# ot_i3c_wrap: IP-XACT component
VLNV tenstorrent.com:ocah:ot_i3c_wrap:1.0

## Address spaces and blocks
ot_i3c_wrap_mmap.ot_i3c_wrap: base 'h0, range 'h6000, width 32

## Registers
Registers are 32-bit, read-write, reset 0x0 unless marked. A register's access mark holds for its fields unless they carry their own. Offsets are from the block's base; lines under a group give offsets from that group; [hi:lo] are bit positions; {n}, {i} and the like mark numbered series; 'fields as' and 'values as' point back to an identical list; <NAME> marks a mode.

## ot_i3c_wrap_mmap.ot_i3c_wrap — Wrapper address map instantiating the per-controller OpenTitan I3C register blocks.
Base 0x00000000
{0x0+0x1000*i} i3c_csr[{i}] (i=0..5) group — I3C Controller/Target
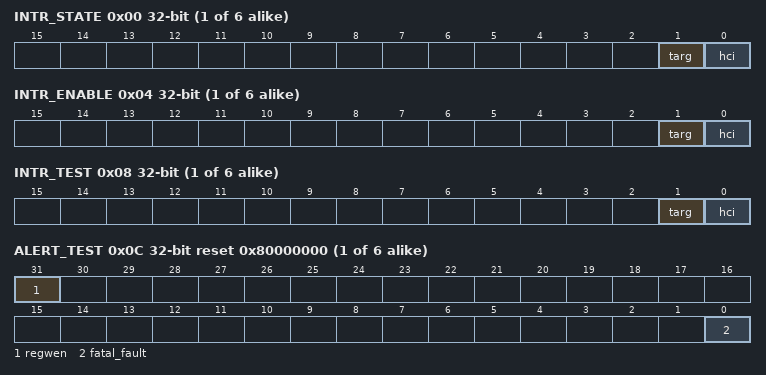
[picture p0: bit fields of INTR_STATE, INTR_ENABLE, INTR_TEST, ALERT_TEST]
  0x00 INTR_STATE ro
    [1] targ — Target interrupt.
    [0] hci — HCI interrupt.
  0x04 INTR_ENABLE
    [1] targ — Enable interrupt when !!INTR_STATE.targ is set.
    [0] hci — Enable interrupt when !!INTR_STATE.hci is set.
  0x08 INTR_TEST wo
    [1] targ — Write 1 to force !!INTR_STATE.targ to 1.
    [0] hci — Write 1 to force !!INTR_STATE.hci to 1.
  0x0C ALERT_TEST access per field reset 0x80000000
    [31] regwen rw write-0-clears — Write 0 to disable alert testing until the next reset.
    [0] fatal_fault wo — Write 1 to trigger one alert event of this kind.
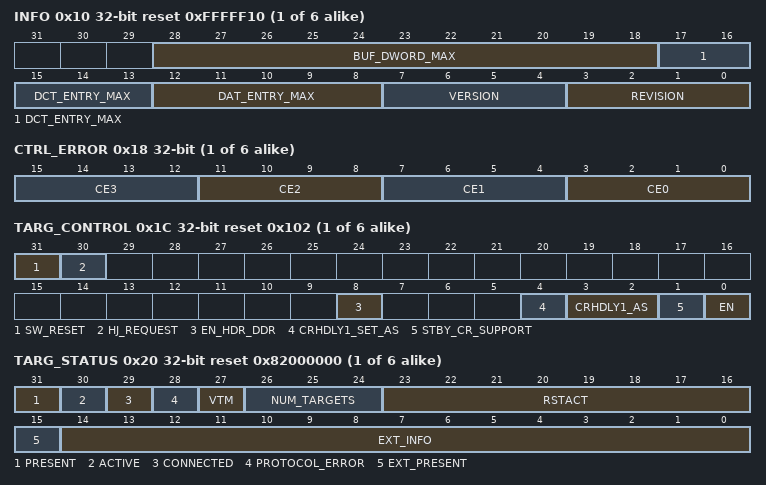
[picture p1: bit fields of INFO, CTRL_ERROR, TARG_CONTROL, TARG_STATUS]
  0x10 INFO ro reset 0xFFFFF10
    [28:18] BUF_DWORD_MAX — Index of the final DWORD of the shared Message Buffer. i.e. one less than its size in DWORDs.
    [17:13] DCT_ENTRY_MAX — Index of the final entry of the HCI Device Characteristics Table. i.e. one less than the number of entries.
    [12:8] DAT_ENTRY_MAX — Index of the final entry of the HCI Device Address Table. i.e. one less than the number of entries.
    [7:4] VERSION — Version number of the IP block.
    [3:0] REVISION — Revision number of the IP block.
  0x14 CTRL_STATUS ro reset 0x80000000
    [31] PRESENT — Indicates the presence of Controller functionality.
  0x18 CTRL_ERROR
    [4n+3:4n] CE{n} write-1-clears (n=0..3) — Count of type {n} Controller Errors.
  0x1C TARG_CONTROL access per field reset 0x102
    [31] SW_RESET wo — Software reset of Target logic. Writing '1' to this field will reset all of the Target-side logic and registers. When the Standby Controller is enabled, this will also reset the registers of the Standby Controller, disabling it. To reset only the Standby Controller whilst it is enabled, software should use the `SOFT_RST` field of the HCI-specified `RESET_CONTROL` register instead, to avoid impacting other Virtual Targets.
    [30] HJ_REQUEST rw — Issue Hot-Join request. This applies to all Virtual Targets since they share a single physical Target. Software shall set this to '1' to issue the request, and the hardware will clear it when the request has been sent and acknowledged.
    [8] EN_HDR_DDR rw — Declare support for HDR-DDR mode in the GETCAPS response of the Target. HDR-DDR mode should normally be enabled, and the ability for software to deactivate HDR-DDR mode is included only as a contingency. This configuration bit shall be modified only before the Target is enabled. For the Controller, the issuing of HDR-DDR communications may be avoided in software by the construction of appropriate Command Descriptors.
    [4] CRHDLY1_SET_AS rw — Set Bus Activity State. This information is returned in response to the CRHDLY form of the GETMXDS CCC.
    [3:2] CRHDLY1_AS rw — Controller Handoff Activity State. This information is returned in response to the CRHDLY form of the GETMXDS CCC.
    [1] STBY_CR_SUPPORT rw — Standby Controller role supported. When set the Controller shall have the option of performing Controller Role Handoff and switching into Standby Controller mode. If this field is clear the Controller will refuse to hand off the bus when requested and will instead remain the Active Controller, thus freeing up the first Virtual Target to operate independently as a dedicated Target device. This version of the IP block does not support Controller Role Handoff.
    [0] EN rw — Target enable. Enable the Target-side logic as a separate I3C device, instead of supporting Standby Controller mode. In this configuration the Controller-side logic must remain the Active Controller and cannot perform Controller Role Handoff.
  0x20 TARG_STATUS access per field reset 0x82000000
    [31] PRESENT ro — Indicates the presence of Target functionality.
    [30] ACTIVE ro — Indicates whether the Target logic is presently active, as opposed to under reset.
    [29] CONNECTED ro — Indicates whether the Target logic is connected to the bus and monitoring traffic.
    [28] PROTOCOL_ERROR ro — Protocol error detected since the last GETSTATUS CCC to read this indicator.
    [27] VTM ro — Vendor Test Mode active, in response to ENTTM.
    [26:24] NUM_TARGETS ro — The number of Targets in this implementation.
    [23:16] RSTACT ro — Configured Target Reset action.
    [15] EXT_PRESENT ro — Indicates whether one or more additional protocols is implemented in the Target hardware. Some protocols require a sufficiently fast response that software involvement is not possible. These may be implemented as an extension within the Target core.
    [14:0] EXT_INFO rw — Extension-specific information.
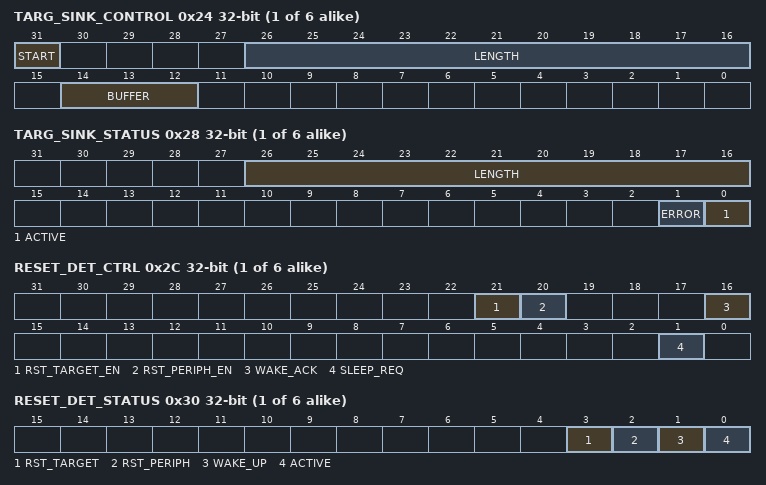
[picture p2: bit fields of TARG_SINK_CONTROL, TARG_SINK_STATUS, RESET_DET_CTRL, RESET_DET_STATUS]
  0x24 TARG_SINK_CONTROL access per field
    [31] START wo — Initiate removal of DWORDs from a transmission buffer. The 'data sink' logic is a mechanism for recovering from aborting or failed transmissions without impacting subsequent, already-queued transfers. Software shall write '1' to this field to start the 'data sink' logic. The ACTIVE field in the corresponding `TARG_SINK_STATUS` register shows whether the logic is still active.
    [26:16] LENGTH rw — Specifies the number of DWORDs to be removed, minus 1. This field instructs the 'data sink' logic to remove a specified number of DWORDs of data from the specified source. Software shall program 'n-1' into this field to remove 'n' DWORDs.
    [14:12] BUFFER rw — Specifies the transmission buffer from which DWORDs are to be removed. 0 - IBI Data buffer. 1 - Virtual Target 0 Tx buffer 2 - Virtual Target 1 Tx buffer...
  0x28 TARG_SINK_STATUS ro
    [26:16] LENGTH — Reports the numbers of DWORDs still to be removed when `ERROR` is asserted. In the event of an error, this value may be used to ascertain how much of the operation was performed. When this field reports 'm', there are still 'm+1' DWORDs to be removed. In the event of successful completion ('ACTIVE' and 'ERROR' both reset) this field is not meaningful and the DWORDs were removed as expected.
    [1] ERROR — Indicates whether the data sink mechanism stopped prematurely. If the specified buffer did not contain sufficient data for the logic to remove the specified number of DWORDs it will set this bit when becoming inactive.
    [0] ACTIVE — Indicates whether the data sink logic is active. This bit becomes set when the operation is started and will be cleared at most a few tens of microseconds later when the operation is complete.
  0x2C RESET_DET_CTRL wo
    [21] RST_TARGET_EN — Enable response to a Whole Target reset request.
    [20] RST_PERIPH_EN — Enable response to a Peripheral reset request.
    [16] WAKE_ACK — Wake acknowledgement.
    [1] SLEEP_REQ — Activate the reset detector prior to entry into 'Deepest Sleep' state.
  0x30 RESET_DET_STATUS ro
    [3] RST_TARGET — Indicates that a Whole Target reset request was received.
    [2] RST_PERIPH — Indicates that a Peripheral reset request was received.
    [1] WAKE_UP — Indicates that a Wake Up request was received.
    [0] ACTIVE — Indicates whether the reset detector is active.
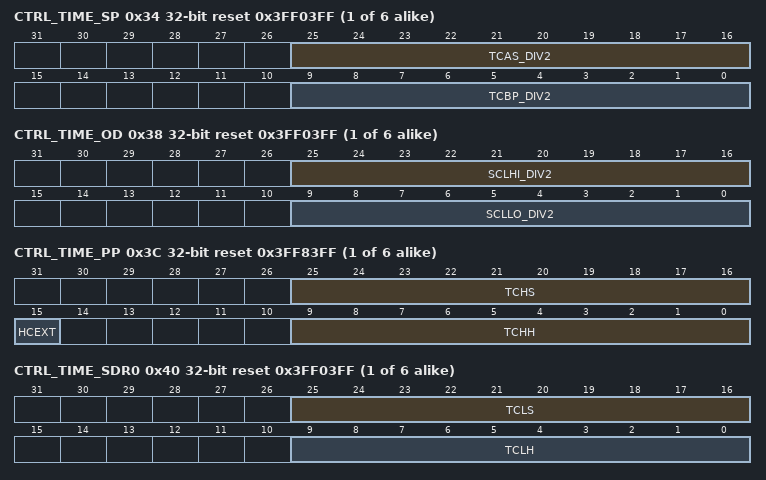
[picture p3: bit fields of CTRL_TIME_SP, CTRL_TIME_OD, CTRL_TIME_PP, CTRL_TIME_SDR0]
  0x34 CTRL_TIME_SP reset 0x3FF03FF
    [25:16] TCAS_DIV2 — Half of the delay between SDA falling and SCL falling in START timing, minus 1. This interval is in terms of the IP clock period. If this field has all bits set then the hardware will calculate a suitable value.
    [9:0] TCBP_DIV2 — Half of the delay between SCL rising and SDA rising in STOP timing, minus 1. This interval is in terms of the IP clock period. If this field has all bits set then the hardware will calculate a suitable value.
  0x38 CTRL_TIME_OD reset 0x3FF03FF
    [25:16] SCLHI_DIV2 — Half of the SCL high interval during Open Drain signaling, minus 1. This interval is in terms of the IP clock period. If this field has all bits set then the hardware will calculate a suitable value.
    [9:0] SCLLO_DIV2 — Half of the SCL low interval during Open Drain signaling, minus 1. This interval is in terms of the IP clock period. If this field has all bits set then the hardware will calculate a suitable value.
  0x3C CTRL_TIME_PP reset 0x3FF83FF
    [25:16] TCHS — Duration of setup phase before falling SCL during Push-Pull signaling, minus 1. This interval is in terms of the IP clock period. If this field has all bits set then the hardware will calculate a suitable value.
    [15] HCEXT — Enable half-cycle SCL extension. If the field `TCHS` has been set to something other than 0x3ff, this bit controls whether the half-cycle SCL extension is enabled. If `TCHS` has all bits set then the hardware will determine this setting automatically. Extending SCL high by half a cycle of the IP clock enables support for other clock frequencies such as 96 MHz.
    [9:0] TCHH — Duration of hold phase after rising SCL during Push-Pull signaling, minus 1. This interval is in terms of the IP clock period. If this field has all bits set then the hardware will calculate a suitable value.
  0x40 CTRL_TIME_SDR0 reset 0x3FF03FF
    [25:16] TCLS — Duration of setup phase before rising SCL when using Push-Pull signaling at SDR0 rate/HDR-DDR, minus 1. This interval is in terms of the IP clock period. If this field has all bits set then the hardware will calculate a suitable value.
    [9:0] TCLH — Duration of hold phase after falling SCL when using Push-Pull signaling at SDR0 rate/HDR-DDR, minus 1. This interval is in terms of the IP clock period. If this field has all bits set then the hardware will calculate a suitable value.
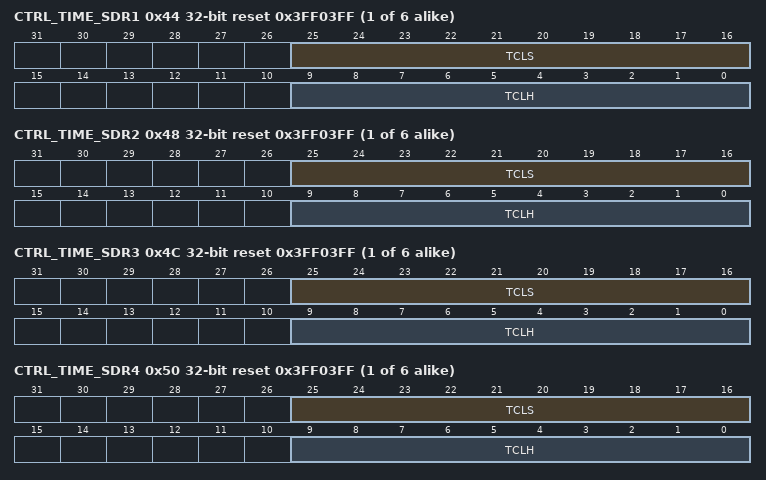
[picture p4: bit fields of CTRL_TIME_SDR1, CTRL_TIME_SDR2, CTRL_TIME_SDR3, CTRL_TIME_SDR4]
  0x44 CTRL_TIME_SDR1 reset 0x3FF03FF
    [25:16] TCLS — Duration of setup phase before rising SCL when using Push-Pull signaling at SDR1 rate, minus 1. This interval is in terms of the IP clock period. If this field has all bits set then the hardware will calculate a suitable value.
    [9:0] TCLH — Duration of hold phase after falling SCL when using Push-Pull signaling at SDR1 rate, minus 1. This interval is in terms of the IP clock period. If this field has all bits set then the hardware will calculate a suitable value.
  0x48 CTRL_TIME_SDR2 reset 0x3FF03FF
    [25:16] TCLS — Duration of setup phase before rising SCL when using Push-Pull signaling at SDR2, minus 1. This interval is in terms of the IP clock period. If this field has all bits set then the hardware will calculate a suitable value.
    [9:0] TCLH — Duration of hold phase after falling SCL when using Push-Pull signaling at SDR2 rate, minus 1. This interval is in terms of the IP clock period. If this field has all bits set then the hardware will calculate a suitable value.
  0x4C CTRL_TIME_SDR3 reset 0x3FF03FF
    [25:16] TCLS — Duration of setup phase before rising SCL when using Push-Pull signaling at SDR3 rate, minus 1. This interval is in terms of the IP clock period. If this field has all bits set then the hardware will calculate a suitable value.
    [9:0] TCLH — Duration of hold phase after falling SCL when using Push-Pull signaling at SDR3 rate, minus 1. This interval is in terms of the IP clock period. If this field has all bits set then the hardware will calculate a suitable value.
  0x50 CTRL_TIME_SDR4 reset 0x3FF03FF
    [25:16] TCLS — Duration of setup phase before rising SCL when using Push-Pull signaling at SDR4 rate, minus 1. This interval is in terms of the IP clock period. If this field has all bits set then the hardware will calculate a suitable value.
    [9:0] TCLH — Duration of hold phase after falling SCL when using Push-Pull signaling at SDR4 rate, minus 1. This interval is in terms of the IP clock period. If this field has all bits set then the hardware will calculate a suitable value.
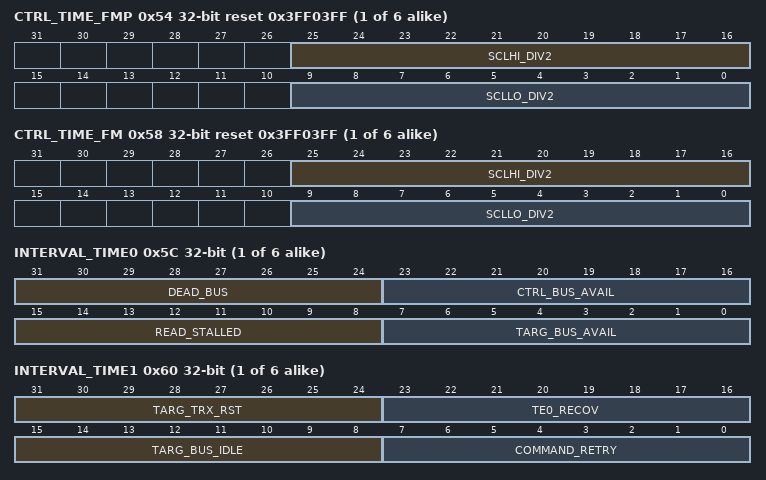
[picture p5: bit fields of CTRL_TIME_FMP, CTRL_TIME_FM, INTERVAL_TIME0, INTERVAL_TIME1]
  0x54 CTRL_TIME_FMP reset 0x3FF03FF
    [25:16] SCLHI_DIV2 — Half of the SCL high interval during I2C Fast Mode Plus signaling, minus 1. This interval is in terms of the IP clock period. If this field has all bits set then the hardware will calculate a suitable value.
    [9:0] SCLLO_DIV2 — Half of the SCL low interval during I2C Fast Mode Plus signaling, minus 1. This interval is in terms of the IP clock period. If this field has all bits set then the hardware will calculate a suitable value.
  0x58 CTRL_TIME_FM reset 0x3FF03FF
    [25:16] SCLHI_DIV2 — Half of the SCL high interval during I2C Fast Mode signaling, minus 1. This interval is in terms of the IP clock period. If this field has all bits set then the hardware will calculate a suitable value.
    [9:0] SCLLO_DIV2 — Half of the SCL low interval during I2C Fast Mode signaling, minus 1. This interval is in terms of the IP clock period. If this field has all bits set then the hardware will calculate a suitable value.
  0x5C INTERVAL_TIME0
    [31:24] DEAD_BUS — Adjustment to the interval of the Dead Bus timer. Default interval: 50 milliseconds. Base weighting: 0x4000 IP clock cycles.
    [23:16] CTRL_BUS_AVAIL — Adjustment to the interval of the Controller Bus Available timer. Default interval: 1 microsecond. Base weighting: 1 IP clock cycle.
    [15:8] READ_STALLED — Adjustment to the interval of the SDA read stall (no Controller SCL activity during Read Transfer) timer. Default interval: 150 microseconds. Base weighting: 0x40 IP clock cycles.
    [7:0] TARG_BUS_AVAIL — Adjustment to the interval of the Target Bus Available timer. Default interval: 1 microsecond. Base weighting: 1 IP clock cycle.
  0x60 INTERVAL_TIME1
    [31:24] TARG_TRX_RST — Adjustment to the Target Reset timer. Default interval: 5 microseconds. Base weighting: 1 IP clock cycle.
    [23:16] TE0_RECOV — Adjustment to the interval after which the Target shall attempt recovery from a Target Error 0 (TE0) condition. Default interval: 60 microseconds. Base weighting: 0x10 IP clock cycles.
    [15:8] TARG_BUS_IDLE — Adjustment to the interval of the Target Bus Idle timer. Default interval: 200 microseconds. Base weighting: 0x40 IP clock cycles.
    [7:0] COMMAND_RETRY — Adjustment to the interval after which NACKed commands are retried. Default interval: 800 microseconds. Base weighting: 0x100 IP clock cycles.
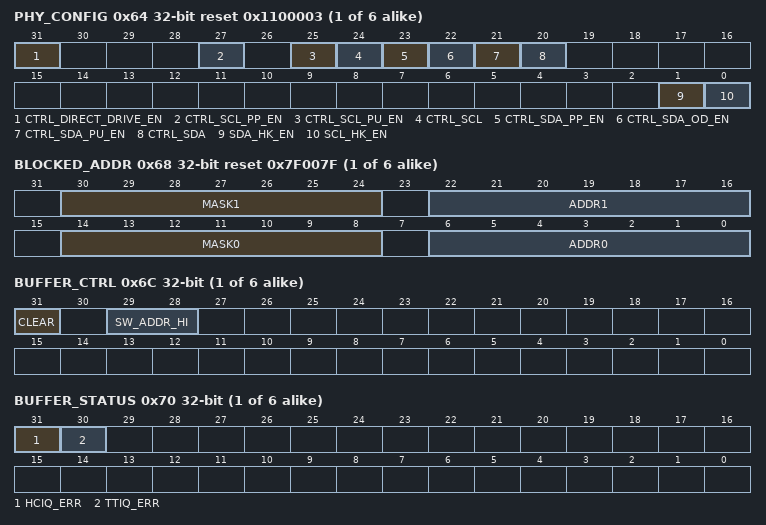
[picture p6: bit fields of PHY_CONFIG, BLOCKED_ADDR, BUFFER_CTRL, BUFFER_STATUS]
  0x64 PHY_CONFIG reset 0x1100003
    [31] CTRL_DIRECT_DRIVE_EN — Enable direct driving of the Serial Clock (SCL) and Serial Data (SDA) lines by software.
    [27] CTRL_SCL_PP_EN — Enable push-pull driving of SCL in direct-driving mode.
    [25] CTRL_SCL_PU_EN — Enable pull-up on SCL in direct-driving mode.
    [24] CTRL_SCL — State of the SCL line when direct-driving is enabled.
    [23] CTRL_SDA_PP_EN — Enable push-pull driving of SDA in direct-driving mode, when open drain driving is not also enabled.
    [22] CTRL_SDA_OD_EN — Enable open drain driving of SDA in direct-driving mode.
    [21] CTRL_SDA_PU_EN — Enable pull-up on SDA in direct-driving mode.
    [20] CTRL_SDA — State of the SDA line when direct-driving is enabled.
    [1] SDA_HK_EN — High-keeper enable for the SDA lane.
    [0] SCL_HK_EN — High-keeper enable for the SCL line.
  0x68 BLOCKED_ADDR reset 0x7F007F
    [30:24] MASK1 — Address mask for the second set of blocked addresses. This mask determines which bits of the device address will be tested and matched against the address in 'ADDR1'. I2C devices are commonly configured with one of a small set of static addresses, differing in only one or two address bits.
    [22:16] ADDR1 — Second blocked address. Accesses to the target address (`TARG_ADDR`) will be blocked if the following expression matches: `(TARG_ADDR & MASK1) == ADDR1` The reset values of `MASK1` and `ADDR1` cannot yield a match, deactivating this check.
    [14:8] MASK0 — Address mask for the first set of blocked addresses. This mask determines which bits of the device address will be tested and matched against the address in 'ADDR0'. I2C devices are commonly configured with one of a small set of static addresses, differing in only one or two address bits.
    [6:0] ADDR0 — First blocked address. Accesses to the target address (`TARG_ADDR`) will be blocked if the following expression matches: `(TARG_ADDR & MASK0) == ADDR0` The reset values of `MASK0` and `ADDR0` cannot yield a match, deactivating this check.
  0x6C BUFFER_CTRL access per field
    [31] CLEAR wo — Software clear of buffer state including the following: All `WPTR` and `RPTR` values are set to the corresponding `MIN` values, emptying all circular buffers. This shall only be used when both the Controller- and the Target-side functionality are disabled.
    [29:28] SW_ADDR_HI rw — Supplies the high address bits when software performs direct accesses to the internal message buffer. The IP may be configured to map part of its internal message buffer into the upper half of the IP address space. This provides more RAM to a memory-limited system when the I3C is not being used, and may be diagnostically useful when it is used. Since half of the IP address space is typically 2 KiB but the message buffer is larger, this field allows software-controlled paging.
  0x70 BUFFER_STATUS
    [31] HCIQ_ERR write-1-clears — Diagnostic error indicator for the Host Controller Interface (HCI) queues. The hardware sets this bit in the event of a write to a full or read-only queue, or a read from an empty or write-only queue. Software shall clear this bit by writing '1'.
    [30] TTIQ_ERR write-1-clears — Diagnostic error indicator for the Target Transaction Interface (TTI) queues. The hardware sets this bit in the event of a write to a full or read-only queue, or a read from an empty or write-only queue. Software shall clear this bit by writing '1'.
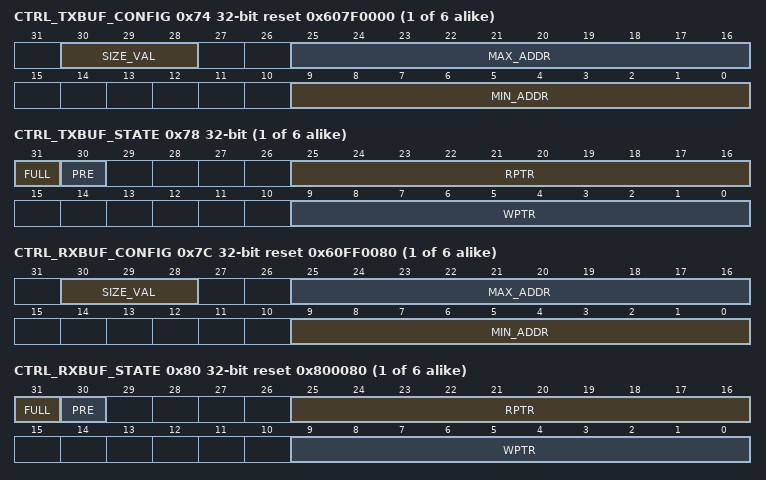
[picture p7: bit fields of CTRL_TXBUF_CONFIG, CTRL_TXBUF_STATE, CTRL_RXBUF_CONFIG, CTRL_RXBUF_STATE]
  0x74 CTRL_TXBUF_CONFIG reset 0x607F0000
    [30:28] SIZE_VAL — Size value presented as `QUEUE_SIZE.TX_DATA_BUFFER_SIZE`. This value is log2(size in DWORDs) - 1.
    [25:16] MAX_ADDR — Maximum address for Controller TX use (inclusive).
    [9:0] MIN_ADDR — Minimum address for Controller TX use.
  0x78 CTRL_TXBUF_STATE ro
    [31] FULL — Indicates if the buffer is full.
    [30] PRE — Indicates if prefetched data is available.
    [25:16] RPTR — Current read pointer.
    [9:0] WPTR — Current write pointer.
  0x7C CTRL_RXBUF_CONFIG reset 0x60FF0080
    [30:28] SIZE_VAL — Size value presented as `QUEUE_SIZE.RX_DATA_BUFFER_SIZE`. This value is log2(size in DWORDs) - 1.
    [25:16] MAX_ADDR — Maximum address for Controller RX use (inclusive).
    [9:0] MIN_ADDR — Minimum address for Controller RX use.
  0x80 CTRL_RXBUF_STATE ro reset 0x800080
    fields as i3c_csr[0].CTRL_TXBUF_STATE
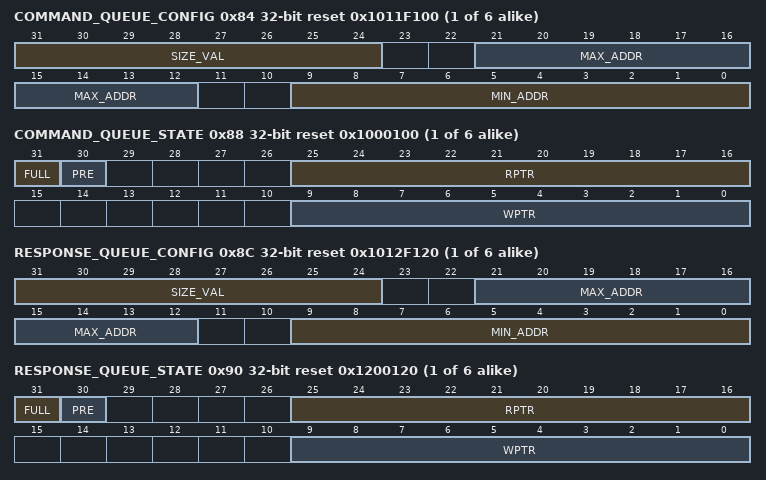
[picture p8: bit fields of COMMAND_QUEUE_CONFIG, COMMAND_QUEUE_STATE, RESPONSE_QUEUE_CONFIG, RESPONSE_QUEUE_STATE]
  0x84 COMMAND_QUEUE_CONFIG reset 0x1011F100
    [31:24] SIZE_VAL — Size value presented as `QUEUE_SIZE.CR_QUEUE_SIZE`.
    [21:12] MAX_ADDR — Maximum address for Command Queue use (inclusive).
    [9:0] MIN_ADDR — Minimum address for Command Queue use.
  0x88 COMMAND_QUEUE_STATE ro reset 0x1000100
    [31] FULL — Indicates if the queue is full.
    [30] PRE — Indicates if prefetched data is available.
    [25:16] RPTR — Current read pointer.
    [9:0] WPTR — Current write pointer.
  0x8C RESPONSE_QUEUE_CONFIG reset 0x1012F120
    [31:24] SIZE_VAL — Size value presented as `ALT_QUEUE_SIZE.ALT_RSP_QUEUE_SIZE`.
    [21:12] MAX_ADDR — Maximum address for Response Queue use (inclusive).
    [9:0] MIN_ADDR — Minimum address for Response Queue use.
  0x90 RESPONSE_QUEUE_STATE ro reset 0x1200120
    fields as i3c_csr[0].COMMAND_QUEUE_STATE
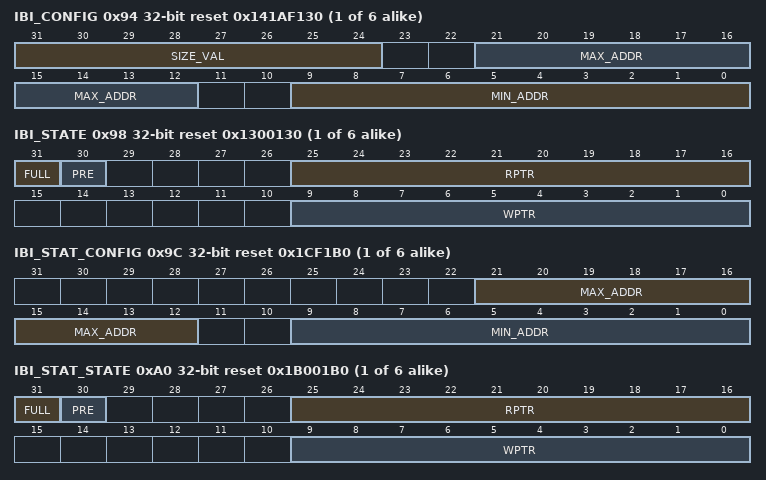
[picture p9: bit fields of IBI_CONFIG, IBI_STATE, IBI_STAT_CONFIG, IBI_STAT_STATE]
  0x94 IBI_CONFIG reset 0x141AF130
    [31:24] SIZE_VAL — Size value presented as `QUEUE_SIZE.IBI_STATUS_SIZE`. This value represents the sum of the IBI Queue and the IBI Status Descriptor FIFO. Since EXT_IBI_QUEUE_EN is set, the actual number of DWORDs is 8 times this value.
    [21:12] MAX_ADDR — Maximum address for IBI Queue use (inclusive).
    [9:0] MIN_ADDR — Minimum address for IBI Queue use.
  0x98 IBI_STATE ro reset 0x1300130
    fields as i3c_csr[0].COMMAND_QUEUE_STATE
  0x9C IBI_STAT_CONFIG reset 0x1CF1B0
    [21:12] MAX_ADDR — Maximum address for IBI Status Descriptor FIFO use (inclusive).
    [9:0] MIN_ADDR — Minimum address for IBI Status Descriptor FIFO use.
  0xA0 IBI_STAT_STATE ro reset 0x1B001B0
    [31] FULL — Indicates if the FIFO is full.
    [30] PRE — Indicates if prefetched data is available.
    [25:16] RPTR — Current read pointer.
    [9:0] WPTR — Current write pointer.
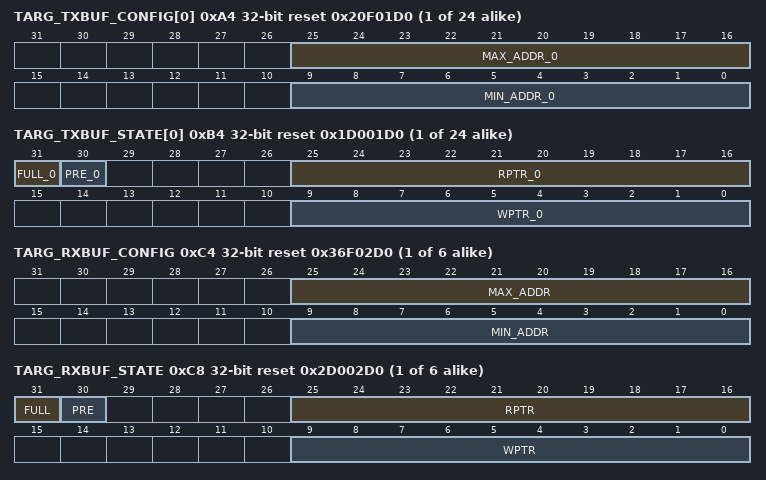
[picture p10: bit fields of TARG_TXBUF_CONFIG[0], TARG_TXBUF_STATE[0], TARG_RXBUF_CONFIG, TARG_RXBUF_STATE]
  {0xA4+4j} TARG_TXBUF_CONFIG[{j}] (j=0..3) reset 0x20F01D0
    [25:16] MAX_ADDR_0 — Maximum address for Target TX use (inclusive). The default addressing apportions the available storage space among the maximum number of Virtual Targets. For configurations employing fewer Virtual Targets, software should modify the configuration.
    [9:0] MIN_ADDR_0 — Minimum address for Target TX use. The default addressing apportions the available storage space among the maximum number of Virtual Targets. For configurations employing fewer Virtual Targets, software should modify the configuration.
  {0xB4+4j} TARG_TXBUF_STATE[{j}] (j=0..3) ro reset 0x1D001D0
    [31] FULL_0 — Indicates if the buffer is full.
    [30] PRE_0 — Indicates if prefetched data is available.
    [25:16] RPTR_0 — Current read pointer.
    [9:0] WPTR_0 — Current write pointer.
  0xC4 TARG_RXBUF_CONFIG reset 0x36F02D0
    [25:16] MAX_ADDR — Maximum address for Target RX use (inclusive).
    [9:0] MIN_ADDR — Minimum address for Target RX use.
  0xC8 TARG_RXBUF_STATE ro reset 0x2D002D0
    fields as i3c_csr[0].CTRL_TXBUF_STATE
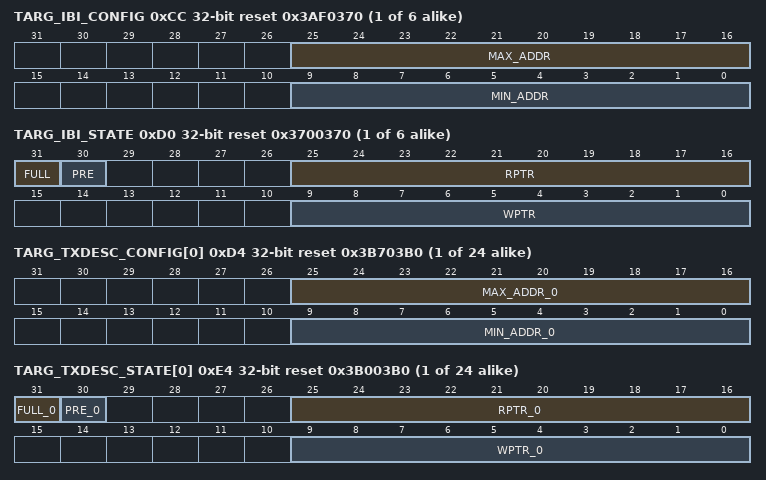
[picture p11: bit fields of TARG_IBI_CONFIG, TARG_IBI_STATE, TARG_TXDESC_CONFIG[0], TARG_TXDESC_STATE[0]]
  0xCC TARG_IBI_CONFIG reset 0x3AF0370
    [25:16] MAX_ADDR — Maximum address for Target RX data use (inclusive).
    [9:0] MIN_ADDR — Minimum address for Target IBI data use.
  0xD0 TARG_IBI_STATE ro reset 0x3700370
    fields as i3c_csr[0].CTRL_TXBUF_STATE
  {0xD4+4j} TARG_TXDESC_CONFIG[{j}] (j=0..3) reset 0x3B703B0
    [25:16] MAX_ADDR_0 — Maximum address for Target 0 Tx Descriptor Queue use (inclusive).
    [9:0] MIN_ADDR_0 — Minimum address for Target 0 Tx Descriptor Queue use.
  {0xE4+4j} TARG_TXDESC_STATE[{j}] (j=0..3) ro reset 0x3B003B0
    [31] FULL_0 — Indicates if the queue is full.
    [30] PRE_0 — Indicates if prefetched data is available.
    [25:16] RPTR_0 — Current read pointer.
    [9:0] WPTR_0 — Current write pointer.
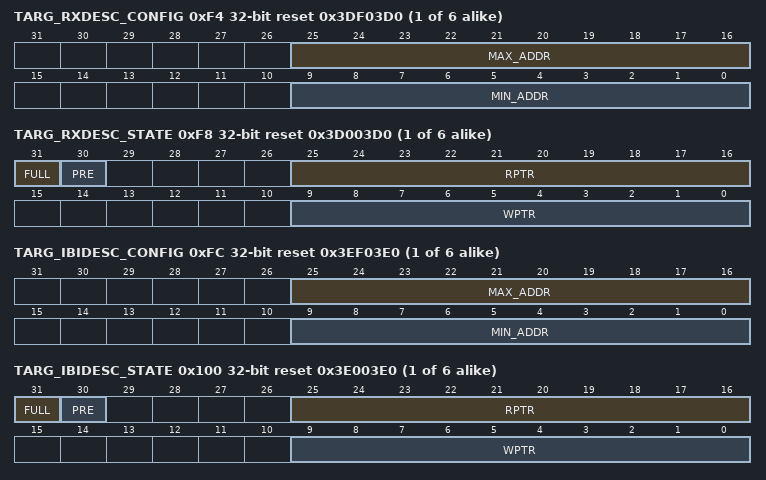
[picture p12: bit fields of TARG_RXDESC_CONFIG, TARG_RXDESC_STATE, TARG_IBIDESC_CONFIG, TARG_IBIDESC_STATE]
  0xF4 TARG_RXDESC_CONFIG reset 0x3DF03D0
    [25:16] MAX_ADDR — Maximum address for Target Rx Descriptor Queue use (inclusive).
    [9:0] MIN_ADDR — Minimum address for Target Rx Descriptor Queue use.
  0xF8 TARG_RXDESC_STATE ro reset 0x3D003D0
    fields as i3c_csr[0].COMMAND_QUEUE_STATE
  0xFC TARG_IBIDESC_CONFIG reset 0x3EF03E0
    [25:16] MAX_ADDR — Maximum address for Target IBI Descriptor Queue use (inclusive).
    [9:0] MIN_ADDR — Minimum address for Target IBI Descriptor Queue use.
  0x100 TARG_IBIDESC_STATE ro reset 0x3E003E0
    fields as i3c_csr[0].COMMAND_QUEUE_STATE
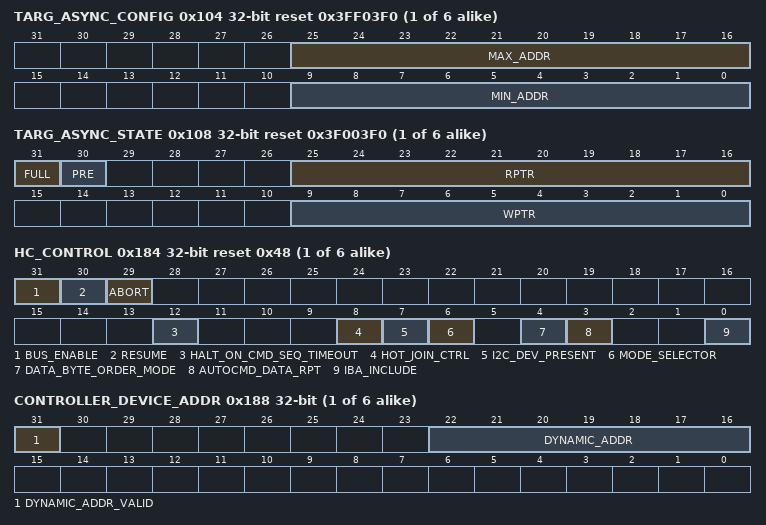
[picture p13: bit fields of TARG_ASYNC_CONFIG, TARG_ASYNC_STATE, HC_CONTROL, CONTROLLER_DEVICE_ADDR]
  0x104 TARG_ASYNC_CONFIG reset 0x3FF03F0
    [25:16] MAX_ADDR — Maximum address for Target Asynchronous Event Queue use (inclusive).
    [9:0] MIN_ADDR — Minimum address for Target Asynchronous Event Queue use.
  0x108 TARG_ASYNC_STATE ro reset 0x3F003F0
    fields as i3c_csr[0].COMMAND_QUEUE_STATE
  0x180 HCI_VERSION ro reset 0x120
    [31:0] VERSION — HCI Version.
  0x184 HC_CONTROL access per field reset 0x48
    [31] BUS_ENABLE rw — Host Controller Bus Enable.
    [30] RESUME rw — Host Controller Resume.
    [29] ABORT rw — Host Controller Abort.
    [12] HALT_ON_CMD_SEQ_TIMEOUT rw — Halt on Command Sequence Timeout.
    [8] HOT_JOIN_CTRL rw — Hot-Join ACK/NACK Control.
    [7] I2C_DEV_PRESENT rw — I2C Device Present on Bus.
    [6] MODE_SELECTOR ro — DMA/PIO Mode Selector.
    [4] DATA_BYTE_ORDER_MODE ro — Data Byte Ordering Mode.
    [3] AUTOCMD_DATA_RPT rw — Auto-Command Data Report.
    [0] IBA_INCLUDE rw — Include I3C Broadcast Address.
  0x188 CONTROLLER_DEVICE_ADDR
    [31] DYNAMIC_ADDR_VALID — Dynamic Address is Valid.
    [22:16] DYNAMIC_ADDR — Device Dynamic Address.
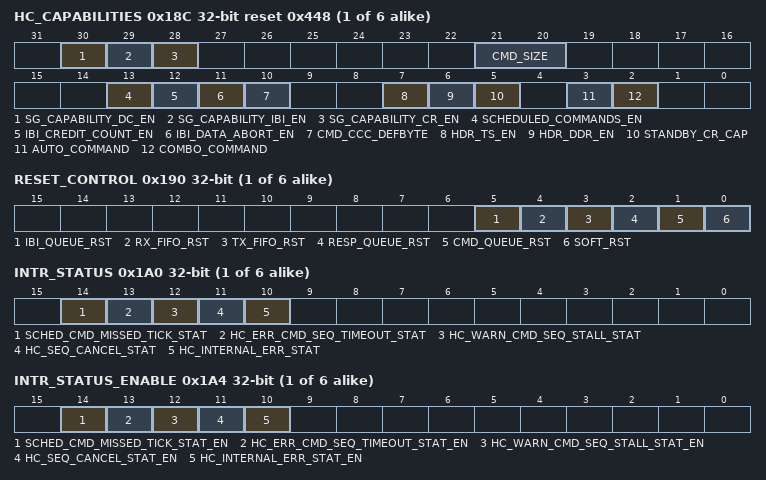
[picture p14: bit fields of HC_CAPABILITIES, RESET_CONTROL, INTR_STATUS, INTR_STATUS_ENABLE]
  0x18C HC_CAPABILITIES ro reset 0x448
    [30] SG_CAPABILITY_DC_EN — Defines whether the Host Controller supports Scatter-Gather for Device Context memory.
    [29] SG_CAPABILITY_IBI_EN — Defines whether the Host Controller supports Scatter-Gather for IBI Status and IBI Data Rings.
    [28] SG_CAPABILITY_CR_EN — Defines whether the Host Controller supports Scatter-Gather for Command and Response Rings.
    [21:20] CMD_SIZE — Defines the size and structure of the Command Descriptor supported by the Host Controller.
    [13] SCHEDULED_COMMANDS_EN — Defines whether the Host Controller supports Scheduled Commands capabilities.
    [12] IBI_CREDIT_COUNT_EN — Defines whether the Host Controller supports Target IBI Credit Counting.
    [11] IBI_DATA_ABORT_EN — Defines whether the Host Controller supports the IBI Data Abort operation.
    [10] CMD_CCC_DEFBYTE — Defines whether the Host Controller supports Transfer Commands that indicate CCCs with Defining Bytes.
    [7] HDR_TS_EN — Defines whether the Host Controller supports HDR-Ternary transfers.
    [6] HDR_DDR_EN — Defines whether the Host Controller supports HDR-DDR transfers.
    [5] STANDBY_CR_CAP — Defines whether the Host Controller supports handoff of the Active Controller role.
    [3] AUTO_COMMAND — Defines whether the Host Controller supports Auto-Command functionality.
    [2] COMBO_COMMAND — Defines whether the Host Controller supports Combo Transfer Command transfers.
  0x190 RESET_CONTROL wo
    [5] IBI_QUEUE_RST — IBI Queue Buffer Software Reset.
    [4] RX_FIFO_RST — Receive Queue Buffer Software Reset.
    [3] TX_FIFO_RST — Transmit Queue Buffer Software Reset.
    [2] RESP_QUEUE_RST — Response Queue Software Reset.
    [1] CMD_QUEUE_RST — Command Queue Software Reset.
    [0] SOFT_RST — Core Software Reset.
  0x194 PRESENT_STATE ro
    [2] AC_CURRENT_OWN — Active Controller.
  0x1A0 INTR_STATUS
    [14] SCHED_CMD_MISSED_TICK_STAT write-1-clears — Scheduled Command Missed Tick.
    [13] HC_ERR_CMD_SEQ_TIMEOUT_STAT write-1-clears — Host Controller Command Sequence Timeout.
    [12] HC_WARN_CMD_SEQ_STALL_STAT write-1-clears — Host Controller Command Sequence Stall.
    [11] HC_SEQ_CANCEL_STAT write-1-clears — Host Controller Cancelled Transaction Sequence.
    [10] HC_INTERNAL_ERR_STAT write-1-clears — Host Controller Internal Error.
  0x1A4 INTR_STATUS_ENABLE
    [14] SCHED_CMD_MISSED_TICK_STAT_EN — Scheduled Command Missed Tick Status Enable.
    [13] HC_ERR_CMD_SEQ_TIMEOUT_STAT_EN — Host Controller Command Sequence Timeout Status Enable.
    [12] HC_WARN_CMD_SEQ_STALL_STAT_EN — Host Controller Command Sequence Stall Status Enable.
    [11] HC_SEQ_CANCEL_STAT_EN — Host Controller Cancelled Transaction Sequence Status Enable.
    [10] HC_INTERNAL_ERR_STAT_EN — Host Controller Internal Error Status Enable.
  0x1A8 INTR_SIGNAL_ENABLE
    [14] SCHED_CMD_MISSED_TICK_SIGNAL_EN — Scheduled Command Missed Tick Signal Enable.
    [13] HC_ERR_CMD_SEQ_TIMEOUT_SIGNAL_EN — Host Controller Command Sequence Timeout Signal Enable.
    [12] HC_WARN_CMD_SEQ_STALL_SIGNAL_EN — Host Controller Command Sequence Stall Signal Enable.
    [11] HC_SEQ_CANCEL_SIGNAL_EN — Host Controller Cancelled Transaction Sequence Signal Enable.
    [10] HC_INTERNAL_ERR_SIGNAL_EN — Host Controller Internal Error Signal Enable.
  0x1AC INTR_FORCE wo
    [14] SCHED_CMD_MISSED_TICK_FORCE — Force Scheduled Command Missed Tick.
    [13] HC_ERR_CMD_SEQ_TIMEOUT_FORCE — Force Host Controller Command Sequence Timeout.
    [12] HC_WARN_CMD_SEQ_STALL_FORCE — Force Host Controller Command Sequence Stall.
    [11] HC_SEQ_CANCEL_FORCE — Force Host Controller Cancelled Transaction Sequence.
    [10] HC_INTERNAL_ERR_FORCE — Force Host Controller Internal Error.
  0x1B0 DAT_SECTION_OFFSET ro reset 0x20880
    [31:28] ENTRY_SIZE — DAT Entry size.
    [18:12] TABLE_SIZE — DAT Table Size.
    [11:0] TABLE_OFFSET — DAT Table Offset.
  0x1B4 DCT_SECTION_OFFSET access per field reset 0x20A80
    [31:28] ENTRY_SIZE ro — DCT Entry size.
    [23:19] TABLE_INDEX rw — DCT Table Index.
    [18:12] TABLE_SIZE ro — DCT Table Size.
    [11:0] TABLE_OFFSET ro — DCT Table Offset.
  0x1B8 RING_HEADERS_SECTION_OFFSET ro
    [15:0] SECTION_OFFSET — Ring Headers Section Offset.
  0x1BC PIO_SECTION_OFFSET ro reset 0x80
    [15:0] SECTION_OFFSET — PIO Section Offset.
  0x1C0 EXT_CAPS_SECTION_OFFSET ro reset 0x120
    [15:0] SECTION_OFFSET — Extended Capabilities Section Offset.
  0x1CC INT_CTRL_CMDS_EN ro reset 0x20F5
    [15:1] MIPI_CMDS_SUPPORTED — MIPI Alliance Commands Supported.
    [0] ICC_SUPPORT — Internal Control Commands Supported.
  0x1D8 IBI_NOTIFY_CTRL
    [3] NOTIFY_IBI_REJECTED — Notify Rejected In-Band Interrupt Request Control.
    [1] NOTIFY_CRR_REJECTED — Notify Rejected Controller Role Request Control.
    [0] NOTIFY_HJ_REJECTED — Notify Rejected Hot-Join Control.
  0x1DC IBI_DATA_ABORT_CTRL access per field
    [31] IBI_DATA_ABORT_MON rw — IBI Data Abort Monitor.
    [20:18] MATCH_STATUS_TYPE wo — Match IBI Status Type.
    [17:16] AFTER_N_CHUNKS wo — Abort After N Chunks.
    [15:8] MATCH_IBI_ID wo — Match IBI Target Address.
  0x1E0 DEV_CTX_BASE_LO ro
    [31:0] BASE_LO — Device Context Base Low.
  0x1E4 DEV_CTX_BASE_HI ro
    [31:0] BASE_HI — Device Context Base High.
  0x1E8 DEV_CTX_SG ro
    [31] BLP — Buffer Vs. List Pointer.
    [15:0] LIST_SIZE
  0x210 QUEUE_THLD_CTRL reset 0x1010101
    [31:24] IBI_STATUS_THLD — IBI Status Threshold.
    [23:16] IBI_DATA_SEGMENT_SIZE
    [15:8] RESP_BUF_THLD — Response Ready Buffer Threshold.
    [7:0] CMD_EMPTY_BUF_THLD — Command Ready Buffer Threshold.
  0x214 DATA_BUFFER_THLD_CTRL reset 0x1010101
    [26:24] RX_START_THLD — Receive Start Threshold in DWORDs. Wait until there are at least 2^(N+1) DWORD entries available before starting a Read Transfer.
    [18:16] TX_START_THLD — Transmit (Transfer) Start Threshold in DWORDs. Wait until there are at least 2^(N+1) DWORDs of data available before starting a Write Transfer.
    [10:8] RX_BUF_THLD — Receive Buffer Threshold. Interrupt triggers when there are at least 2^(N+1) Rx Buffer DWORDs of data available.
    [2:0] TX_BUF_THLD — Transmit Buffer Threshold. Interrupt triggers when there are at least 2^(N+1) Tx Buffer DWORD entries available.
  0x218 QUEUE_SIZE ro reset 0x6061410
    [31:24] TX_DATA_BUFFER_SIZE — Transmit Data Buffer Size.
    [23:16] RX_DATA_BUFFER_SIZE — Receive Data Buffer Size.
    [15:8] IBI_STATUS_SIZE — IBI Queue Size.
    [7:0] CR_QUEUE_SIZE — Command/Response Queue Size.
  0x21C ALT_QUEUE_SIZE ro reset 0x11000010
    [28] EXT_IBI_QUEUE_EN — Extended IBI Queue Size.
    [24] ALT_RESP_QUEUE_EN — Alternate Response Queue.
    [7:0] ALT_RESP_QUEUE_SIZE — Alternate Response Queue Size.
  0x220 PIO_INTR_STATUS access per field
    [9] TRANSFER_ERR_STAT rw write-1-clears — Transfer Error Status.
    [5] TRANSFER_ABORT_STAT rw write-1-clears — Transfer Abort Status.
    [4] RESP_READY_STAT ro — Response Ready Status.
    [3] CMD_QUEUE_READY_STAT ro — Command Queue Ready Status.
    [2] IBI_STATUS_THLD_STAT ro — IBI Status Threshold Status.
    [1] RX_THLD_STAT ro — Rx Data Buffer Threshold Status.
    [0] TX_THLD_STAT ro — Tx Data Buffer Threshold Status.
  0x224 PIO_INTR_STATUS_ENABLE
    [9] TRANSFER_ERR_STAT_EN — Transfer Error Status Enable.
    [5] TRANSFER_ABORT_STAT_EN — Transfer Abort Status Enable.
    [4] RESP_READY_STAT_EN — Response Ready Status Enable.
    [3] CMD_QUEUE_READY_STAT_EN — Command Queue Ready Status Enable.
    [2] IBI_STATUS_THLD_STAT_EN — IBI Status Threshold Status Enable.
    [1] RX_THLD_STAT_EN — Rx Data Buffer Threshold Status Enable.
    [0] TX_THLD_STAT_EN — Tx Data Buffer Threshold Status Enable.
  0x228 PIO_INTR_SIGNAL_ENABLE
    [9] TRANSFER_ERR_SIGNAL_EN — Transfer Error Signal Enable.
    [5] TRANSFER_ABORT_SIGNAL_EN — Transfer Abort Signal Enable.
    [4] RESP_READY_SIGNAL_EN — Response Ready Signal Enable.
    [3] CMD_QUEUE_READY_SIGNAL_EN — Command Queue Ready Signal Enable.
    [2] IBI_STATUS_THLD_SIGNAL_EN — IBI Status Threshold Signal Enable.
    [1] RX_THLD_SIGNAL_EN — Rx Data Buffer Threshold Signal Enable.
    [0] TX_THLD_SIGNAL_EN — Tx Data Buffer Threshold Signal Enable.
  0x22C PIO_INTR_FORCE wo
    [9] TRANSFER_ERR_FORCE — Force Transfer Error.
    [5] TRANSFER_ABORT_FORCE — Force Transfer Abort.
    [4] RESP_READY_FORCE — Force Response Ready.
    [3] CMD_QUEUE_READY_FORCE — Force Command Queue Ready.
    [2] IBI_THLD_FORCE — Force IBI Status Threshold.
    [1] RX_THLD_FORCE — Force Rx Data Buffer Threshold.
    [0] TX_THLD_FORCE — Force Tx Data Buffer Threshold.
  0x230 PIO_CONTROL reset 0x1
    [2] ABORT — PIO Abort Request.
    [1] RS — PIO Run/Stop Request.
    [0] ENABLE — PIO Queues Enable Request.
  0x2A0 ID_EXTCAP_HEADER ro reset 0x401
    [23:8] CAP_LENGTH — Capability Structure Length in DWORDs.
    [7:0] CAP_ID — Extended Capability ID
  0x2A4 COMP_MANUFACTURER ro
    [31:0] MIPI_VENDOR_ID — MIPI-assigned Manufacturer ID for the Host Controller.
  0x2A8 COMP_VERSION ro
    [31:0] I3C_VER_ID — Vendor-assigned component version for the Host Controller.
  0x2AC COMP_TYPE ro
    [31:0] I3C_PRODUCT_ID — Vendor-assigned component type for the Host Controller.
  0x2B0 CTRL_CFG_EXTCAP_HEADER ro reset 0x202
    fields as i3c_csr[0].ID_EXTCAP_HEADER
  0x2B4 CONTROLLER_CONFIG ro reset 0x10
    [5:4] OPERATION_MODE — Controller Operation Mode. 0x1 : Controller Role functionality only. 0x2 : Target Role functionality only. 0x3 : Both Controller Role and Target Role functionality.
  0x2B8 DBR_EXTCAP_HEADER ro reset 0x20B
    fields as i3c_csr[0].ID_EXTCAP_HEADER
  0x2BC DBR_ENGAGE wo
    [22:16] DBR_IBI_ADDRESS — IBI Address.
    [9:8] DBR_ASX_TIMING — Activity State Timing.
    [6:4] DBR_MODE — Engagement Mode.
    [3:0] DBR_VERIF_KEY — Verification Key.
  0x2C0 DEBUG_EXTCAP_HEADER ro reset 0x60C
    fields as i3c_csr[0].ID_EXTCAP_HEADER
  0x2C4 QUEUE_STATUS_LEVEL ro reset 0x10
    [28:24] IBI_STATUS_CNT — IBI Buffer Status Count.
    [23:16] IBI_BUFFER_LVL — IBI Buffer Level.
    [15:8] RESPONSE_BUFFER_LVL — Response Buffer Level.
    [7:0] CMD_QUEUE_FREE_LVL — Command Queue Free Buffer Level.
  0x2C8 DATA_BUFFER_STATUS_LEVEL ro reset 0x80
    [15:8] RX_BUF_LVL — Rx Data Buffer Status Count.
    [7:0] TX_BUF_FREE_LVL — Tx Data Buffer Status Count.
  0x2CC PRESENT_STATE_DEBUG ro reset 0x3
    [27:24] CMD_TID — Command Transaction ID.
    [21:16] BCL_TFR_ST_STATUS — Bus Controller Logic State.
    [13:8] BCL_TFR_STATUS — Bus Controller Logic Transfer Type Status.
    [1] SDA_LINE_SIGNAL_LEVEL
    [0] SCL_LINE_SIGNAL_LEVEL
  0x2D0 MX_ERROR_COUNTERS ro
    [7:0] CE2_ERROR_COUNT — CE2 Error Counter; resets to zero when read.
  0x2D4 SCHED_CMDS_DEBUG ro
    [21] ERR_OCCURRED — Error Occurred.
    [20:16] TICK_INTERVAL — Tick Interval Number.
    [15:8] ENTITY_ID
    [7] ERR_TYPE — Error Type.
    [6:4] INST_ID — Instance ID.
    [3:0] SCHED_HANDLER — Scheduled Command Handler Type.
  0x2D8 STBY_CR_EXTCAP_HEADER ro reset 0xE12
    fields as i3c_csr[0].ID_EXTCAP_HEADER
  0x2DC STBY_CR_CONTROL access per field reset 0x100C
    [31:30] STBY_CR_ENABLE_INIT rw — Host Controller Secondary Controller Enable. 0 - DISABLED: Secondary Controller operation is disabled. 1 - ACM_INIT: Enabled, but Host Controller initializes in Active Controller mode. 2 - SCM_RUNNING: Enabled, initializes in Standby Controller mode. 3 - SCM_HOT_JOIN: Enabled, Host Controller conditionally becomes a Hot-Joining Device before operating in Standby Controller mode.
    [20] RSTACT_DEFBYTE_02 rw — RSTACT Support DefByte 0x02
    [15] DAA_ENTDAA_ENABLE rw — Dynamic Address Method Enable.
    [14] DAA_SETDASA_ENABLE rw — Dynamic Address Method Enable.
    [13] DAA_SETAASA_ENABLE rw — Dynamic Address Method Enable.
    [12] TARGET_XACT_ENABLE rw — Target Transaction Interface Servicing Enable.
    [10:8] BCAST_CCC_IBI_RING rw — Ring Bundle IBI Selector for Broadcast CCC Capture.
    [5] CR_REQUEST_SEND wo — Send Controller Role Request.
    [4] HANDOFF_DEEP_SLEEP rw
    [3] PRIME_ACCEPT_GETACCCR rw — Prime to Accept Controller Role.
    [2] ACR_FSM_OP_SELECT rw — Active Controller Select.
    [1] HANDOFF_DELAY_NACK rw write-1-clears
    [0] PENDING_RX_NACK rw write-1-clears
  0x2E0 STBY_CR_DEVICE_ADDR access per field
    [31] DYNAMIC_ADDR_VALID ro — Dynamic Address is Valid.
    [22:16] DYNAMIC_ADDR ro — Device Dynamic Address.
    [15] STATIC_ADDR_VALID rw — Static Address is Valid.
    [6:0] STATIC_ADDR rw — Device Static Address.
  0x2E4 STBY_CR_CAPABILITIES ro reset 0xF020
    [15] DAA_ENTDAA_SUPPORT — Dynamic Address Assignment with ENTDAA is supported.
    [14] DAA_SETDASA_SUPPORT — Dynamic Address Assignment with SETDASA is supported.
    [13] DAA_SETAASA_SUPPORT — Dynamic Address Assignment with SETAASA is supported.
    [12] TARGET_XACT_SUPPORT — I3C Target Transaction Interface is supported.
    [5] SIMPLE_CRR_SUPPORT — Simple Controller Role Request is supported.
  0x2EC STBY_CR_STATUS ro
    [8] HJ_REQ_STATUS — Hot-Join Request Status.
    [7:5] SIMPLE_CRR_STATUS — Simple Controller Role Request Status.
    [2] AC_CURRENT_OWN — Active Controller.
  0x2F0 STBY_CR_DEVICE_CHAR access per field reset 0x60000000
    [31:29] BCR_FIXED ro — Bus Characteristics Register Fixed.
    [28:24] BCR_VAR rw — Bus Characteristics Register Variable.
    [23:16] DCR rw — Device Characteristics Register.
    [15:1] PID_HI rw — Device Provisioned ID High.
  0x2F4 STBY_CR_DEVICE_PID_LO
    [31:0] PID_LO — Device Provisioned ID Low.
  0x2F8 STBY_CR_INTR_STATUS
    [19] CCC_FATAL_RSTDAA_ERR_STAT write-1-clears — CCC Fatal RSTDAA Error Status.
    [18] CCC_UNHANDLED_NACK_STAT write-1-clears — CCC Unhandled NACK Status.
    [17] CCC_PARAM_MODIFIED_STAT write-1-clears — CCC Parameter Modified Status.
    [16] STBY_CR_OP_RSTACT_STAT write-1-clears — Secondary Controller Operation Reset Action.
    [14] STBY_CR_ACCEPT_ERR_STAT write-1-clears — Secondary Controller Transition Error Status.
    [13] STBY_CR_ACCEPT_OK_STAT write-1-clears — Secondary Controller Transition OK Status.
    [12] STBY_CR_ACCEPT_NACKED_STAT write-1-clears — Secondary Controller Transition NACKed.
    [11] STBY_CR_DYN_ADDR_STAT write-1-clears — Secondary Controller Dynamic Address Status.
    [10] CRR_RESPONSE_STAT write-1-clears — Controller Role Request Response Status.
    [3] ACR_HANDOFF_ERR_M3_STAT write-1-clears — Controller Role Handoff Error Type CE3 Recovery.
    [2] ACR_HANDOFF_ERR_FAIL_STAT write-1-clears — Controller Role Handoff Error Due To Failure.
    [1] ACR_HANDOFF_OK_PRIMED_STAT write-1-clears — Controller Role Handoff OK and Primed to Accept.
    [0] ACR_HANDOFF_OK_REMAIN_STAT write-1-clears — Controller Role Handoff OK and Will Remain Secondary Controller.
  0x300 STBY_CR_INTR_SIGNAL_ENABLE reset 0xC0000
    [19] CCC_FATAL_RSTDAA_ERR_SIGNAL_EN — CCC Fatal RSTDAA Error Signal Enable.
    [18] CCC_UNHANDLED_NACK_SIGNAL_EN — CCC Unhandled NACK Signal Enable.
    [17] CCC_PARAM_MODIFIED_SIGNAL_EN — CCC Parameter Modified Signal Enable.
    [16] STBY_CR_OP_RSTACT_SIGNAL_EN — Secondary Controller Operation Reset Action Signal Enable.
    [14] STBY_CR_ACCEPT_ERR_SIGNAL_EN — Secondary Controller Transition Error Signal Enable.
    [13] STBY_CR_ACCEPT_OK_SIGNAL_EN — Secondary Controller Transition OK Signal Enable.
    [12] STBY_CR_ACCEPT_NACKED_SIGNAL_EN — Secondary Controller Transition NACKed Signal Enable.
    [11] STBY_CR_DYN_ADDR_SIGNAL_EN — Secondary Controller Dynamic Address Signal Enable.
    [10] CRR_RESPONSE_SIGNAL_EN — Controller Role Request Response Signal Enable.
    [3] ACR_HANDOFF_ERR_M3_SIGNAL_EN — Controller Role Handoff Error Type CE3 Recovery Signal Enable.
    [2] ACR_HANDOFF_ERR_FAIL_SIGNAL_EN — Controller Role Handoff Error Due To Failure Signal Enable.
    [1] ACR_HANDOFF_OK_PRIMED_SIGNAL_EN — Controller Role Handoff OK and Primed to Accept Signal Enable.
    [0] ACR_HANDOFF_OK_REMAIN_SIGNAL_EN — Controller Role Handoff OK and Will Remain Secondary Signal Enable.
  0x304 STBY_CR_INTR_FORCE wo
    [19] CCC_FATAL_RSTDAA_ERR_FORCE — Force CCC Fatal RSTDAA Error.
    [18] CCC_UNHANDLED_NACK_FORCE — Force CCC Unhandled NACK.
    [17] CCC_PARAM_MODIFIED_FORCE — Force CCC Parameter Modified.
    [16] STBY_CR_OP_RSTACT_FORCE — Force Secondary Controller Operation Reset Action.
    [14] STBY_CR_ACCEPT_ERR_FORCE — Force Secondary Controller Transition Error.
    [13] STBY_CR_ACCEPT_OK_FORCE — Force Secondary Controller Transition OK.
    [12] STBY_CR_ACCEPT_NACKED_FORCE — Force Secondary Controller Transition NACKed.
    [11] STBY_CR_DYN_ADDR_FORCE — Force Secondary Controller Dynamic Address Status.
    [10] CRR_RESPONSE_FORCE — Force Controller Role Request Response.
  0x308 STBY_CR_CCC_CONFIG_GETCAPS
    [11:8] F2_CRCAP2_DEV_INTERACT — GETCAPS CCC CRCAPS Byte 2.
    [2:0] F2_CRCAP1_BUS_CONFIG — GETCAPS CCC CRCAPS Byte 1.
  0x30C STBY_CR_CCC_CONFIG_RSTACT_PARAMS access per field reset 0x80000000
    [31] RESET_DYNAMIC_ADDR rw — Reset Dynamic Address After Target Reset.
    [23:16] RESET_TIME_TARGET rw — Time to Reset Target.
    [15:8] RESET_TIME_PERIPHERAL rw — Time to Reset Peripheral.
    [7:0] RST_ACTION ro — Defining Byte of the RSTACT CCC.
  0x310 TTI_EXTCAP_HEADER ro reset 0x59C8
    fields as i3c_csr[0].ID_EXTCAP_HEADER
  0x314 TARG_INTR_STATUS ro
    [31] TE_STAT — Target Error Status.
    [n+16] TX{n}_DESC_READY_STAT (n=0..3) — Target {n} Tx Descriptor Queue Ready Status. Asserted when the Tx Descriptor Queue has at least the requested amount of space, see `TARG_TX_THLD_CTRL.TX_DESC_EMPTY_THLD`.
    [n+8] TX{n}_THLD_STAT (n=0..3) — Target {n} Tx Data Buffer Threshold Status. Asserted when the requested amount of space is available in the Tx Data Buffer, see `TARG_TX_THLD_CTRL.TX_BUF_FREE_THLD`.
    [6] ASYNC_EVT_OVF_STAT — Asynchronous Event Queue Overflow Status.
    [5] RX_BUFFER_OVF_STAT — Rx Data Buffer Overflow Status.
    [4] TRANSFER_ERR_STAT — Transfer Error Status.
    [3] TRANSFER_ABORT_STAT — Transfer Abort Status.
    [2] ASYNC_EVT_READY_STAT — Asynchronous Event Queue Ready Status.
    [1] IBI_STATUS_THLD_STAT — IBI Status Threshold Status.
    [0] RX_DESC_READY_STAT — Rx Descriptor Queue Ready Status.
  0x318 TARG_INTR_STATUS_ENABLE
    [31] TE_STAT_EN — Target Error Status Enable.
    [n+16] TX{n}_DESC_READY_STAT_EN (n=0..3) — Target {n} Tx Descriptor Queue Ready Status Enable.
    [n+8] TX{n}_THLD_STAT_EN (n=0..3) — Target {n} Tx Data Buffer Threshold Status Enable.
    [6] ASYNC_EVT_OVF_STAT_EN — Asynchronous Event Queue Overflow Status Enable.
    [5] RX_BUFFER_OVF_STAT_EN — Rx Data Buffer Overflow Status Enable.
    [4] TRANSFER_ERR_STAT_EN — Transfer Error Status Enable.
    [3] TRANSFER_ABORT_STAT_EN — Transfer Abort Status Enable.
    [2] ASYNC_EVT_READY_STAT_EN — Asynchronous Event Queue Ready Status Enable.
    [1] IBI_STATUS_THLD_STAT_EN — IBI Status Threshold Status Enable.
    [0] RX_DESC_READY_STAT_EN — Rx Descriptor Queue Ready Status Enable.
  0x31C TARG_INTR_SIGNAL_ENABLE
    [31] TE_SIGNAL_EN — Target Error Signal Enable.
    [n+16] TX{n}_DESC_READY_SIGNAL_EN (n=0..3) — Target {n} Tx Descriptor Queue Ready Signal Enable.
    [n+8] TX{n}_THLD_SIGNAL_EN (n=0..3) — Target {n} Tx Data Buffer Threshold Signal Enable.
    [6] ASYNC_EVT_OVF_SIGNAL_EN — Asynchronous Event Queue Overflow Signal Enable.
    [5] RX_BUFFER_OVF_SIGNAL_EN — Rx Data Buffer Overflow Signal Enable.
    [4] TRANSFER_ERR_SIGNAL_EN — Transfer Error Signal Enable.
    [3] TRANSFER_ABORT_SIGNAL_EN — Transfer Abort Signal Enable.
    [2] ASYNC_EVT_READY_SIGNAL_EN — Asynchronous Event Queue Ready Signal Enable.
    [1] IBI_STATUS_THLD_SIGNAL_EN — IBI Status Threshold Signal Enable.
    [0] RX_DESC_READY_SIGNAL_EN — Rx Descriptor Queue Ready Signal Enable.
  0x320 TARG_INTR_FORCE wo
    [31] TE_FORCE — Force Target Error.
    [n+16] TX{n}_DESC_READY_FORCE (n=0..3) — Force Target {n} Tx Descriptor Queue Ready.
    [n+8] TX{n}_THLD_FORCE (n=0..3) — Force Target {n} Tx Data Buffer Threshold.
    [6] ASYNC_EVT_OVF_FORCE — Force Asynchronous Event Queue Overflow.
    [5] RX_BUFFER_OVF_FORCE — Force Rx Data Buffer Overflow.
    [4] TRANSFER_ERR_FORCE — Force Transfer Error.
    [3] TRANSFER_ABORT_FORCE — Force Transfer Abort.
    [2] ASYNC_EVT_READY_FORCE — Force Asynchronous Event Queue Ready.
    [1] IBI_THLD_FORCE — Force IBI Status Threshold.
    [0] RX_DESC_READY_FORCE — Force Rx Descriptor Queue Ready.
  0x324 TARG_PIO_CONTROL
    [27:24] ABORT — Allows software to abort transmission for each Virtual Target in turn. Writing 1 to the corresponding bit will abort any in-progress transmission from that Virtual Target. Transmission will enter the Suspended state and will not resume until the Suspended state is cleared.
    [19:16] SUSPENDED write-1-clears — Indicates, for each Virtual Target in turn, whether transmission has been suspended. If an error occurs during transmission, the corresponding bit will be set automatically by hardware. Software use of the Abort mechanism described above also causes this bit to become set. It remains asserted until the software writes a 1 to clear this bit.
    [1] IBI_ABORT — Allows software to abort transmission of In-Band Interrupts. Writing 1 to this bit will abort any in-progress IBI transmission. IBI transmission will enter the Suspended stateand will not resume until the Suspended state is cleared.
    [0] IBI_SUSPENDED write-1-clears — Indicates whether transmission of In-Band Interrupts has been suspended. If an error occurs during transmission, this bit will be set automatically by hardware. Software use of the IBI Abort mechanism described above also causes this bit to become set. It remains asserted until the software writes a 1 to clear this bit.
  0x328 TARG_ASYNC_EVT_CONTROL
    [31] QUEUE_RESET write-1-clears — Write 1 to reset the Asynchronous Event Queue.
    [7] BUS_EVENTS — Report I3C Bus Events.
    [6] IBI_SUSPEND — Report Suspension of In-Band Interrupt transmission.
    [5] TX_SUSPEND — Report Suspension of Target transmissions.
    [4] IBI_NOTIFY — Notify results of In-Band Interrupt transmissions.
    [3] TX_NOTIFY — Notify results of Target transmissions.
    [2] DIR_GET_CCC — Capture `Direct GET` CCC traffic.
    [1] DIR_SET_CCC — Capture `Direct SET` CCC traffic.
    [0] BCST_CCC — Capture `Broadcast CCC` traffic.
  0x32C TARG_ERROR
    [31:28] DBR write-1-clears — Count of Dead Bus Recovery attempts. Write 4'hf to clear the error count.
    [4n+3:4n] TE{n} write-1-clears (n=0..6) — Count of type {n} Target Errors. Write 4'hf to clear the error count.
  0x330 TARG_QUEUE_THLD_CTRL reset 0x1000100
    [31:24] IBI_STATUS_THLD — IBI Status Threshold. Interrupt is issued when the IBI Status Descriptor Queue has space available for at least N entries. 0: Do not raise any interrupts.
    [15:8] RX_DESC_THLD — Rx Descriptor Queue Threshold. Interrupt is issued when the Rx Descriptor Queue contains at least N descriptors. 0: Do not raise any interrupts.
  0x334 TARG_QUEUE_STATUS_LEVEL ro
    [27:16] ASYNC_EVT_LVL — The number of Asynchronous Event descriptors in the queue.
    [7:0] RX_DESC_LVL — The number of descriptors present in the Rx Descriptor queue.
  0x338 TARG_BUF_THLD_CTRL reset 0x10000001
    [30:28] RX_START_THLD — Receive Start Threshold in DWORDs. Wait until there are at least 2^(N+1) DWORD available before accepting a Private Write transfer. If the Active Controller attempts to perform a write transfer when this condition is not met, it will be NACKed.
    [11:0] RX_SEGMENT_SIZE — Maximum length of received data segment, minus 1. Received data is divided into DWORDs of no more than this length.
  0x33C TARG_BUF_STATUS_LEVEL ro reset 0x400000 (reset mask 0xFFF0000)
    [27:16] IBI_FREE_LVL — The available space (in DWORDs) in the Target IBI queue.
    [11:0] RX_BUF_LVL — The number of DWORDs of data present in the Rx Buffer.
  {0x340+4j} TARG_RW_LEN[{j}] (j=0..3) reset 0xFFFFFFFF
    [31:16] MWL_0 — Maximum Write transfer Length, in bytes.
    [15:0] MRL_0 — Maximum Read transfer Length, in bytes.
  0x350 TARG_IBI_LEN reset 0xFFFFFFFF
    [8n+7:8n] IBI_LEN_{n} (n=0..3) — Maximum length of IBI data payload, in bytes.
  {0x354+4j} TARG_EVENT_ENABLE[{j}] (j=0..3) ro reset 0x7
    [2] ENHJ_0 — If 1 then Hot-Join requests are enabled for this Target.
    [1] ENCR_0 — If 1 then Controller Role Requests are enabled for this Target.
    [0] ENINT_0 — If 1 then In-Band Interrupts are enabled for this Target.
  0x364 TARG_STATE_DEBUG ro reset 0x3
    [31:24] TRX_STATE — Transceiver state.
    [23:16] FSM_STATE — Core FSM state.
    [15:12] BUS_MODE — Current bus mode.
    [9] BUS_IDLE — Reports whether the Bus Idle condition is met at this instant.
    [8] BUS_AVAIL — Reports whether the Bus Available condition is met at this instant.
    [1] SDA_LINE_SIGNAL_LEVEL
    [0] SCL_LINE_SIGNAL_LEVEL
  0x368 TARG_ENABLE
    [n] ENABLE_{n} (n=0..3) — Enable virtual target. A disabled target will not participate in address assignment or respond to bus traffic.
  {0x36C+4j} TARG_GROUP[{j}] (j=0..7)
    [11:8] TARGETS_0 — The set of virtual targets subscribed to this group address. If zero, this entry in the list of group addresses is unused.
    [6:0] GROUP_ADDR_0 — Group address, iff the entry is used. If software sets this address to zero and TARGETS to non-zero, all I3C traffic will be captured as if addressed to the selected Target(s).
  {0x38C+4j} TARG_TX_THLD_CTRL[{j}] (j=0..3) reset 0x10010001
    [31:28] TX_START_THLD_0 — Transmit (Transfer) Start Threshold in DWORDs. Wait until there are at least 2^(N+1) DWORDs of data available before responding to a Read Transfer request.
    [23:16] TX_DESC_EMPTY_THLD_0 — Tx Descriptor Queue Threshold. Interrupt is issued when the Tx Descriptor Queue contains at least N empty entries. 0: Do not raise an interrupt.
    [11:0] TX_BUF_FREE_THLD_0 — Transmit Buffer Threshold. Interrupt triggers when there are at least N DWORDs of free space in the Tx Data Buffer. 0: Do not raise an interrupt.
  {0x39C+4j} TARG_TX_QUEUE_STATUS_LEVEL[{j}] (j=0..3) ro reset 0x80040
    [23:16] TX_DESC_FREE_LVL_0 — The number of free Tx Descriptor Queue entries.
    [11:0] TX_BUF_FREE_LVL_0 — The number of free DWORDs in the Tx Buffer.
  {0x3AC+4j} TARG_ADDR[{j}] (j=0..3)
    [31] DYNAMIC_ADDR_VALID_0 — Dynamic Address is Valid.
    [22:16] DYNAMIC_ADDR_0 — Device Dynamic Address.
    [15] STATIC_ADDR_VALID_0 — Static Address is Valid.
    [6:0] STATIC_ADDR_0 — Device Static Address.
  {0x3BC+4j} TARG_CHAR[{j}] (j=0..3) reset 0x3E000000
    [31:24] BCR_0 — Bus Characteristics Register.
    [23:16] DCR_0 — Device Characteristics Register.
    [15:0] PID_HI_0 — High part of Provisioned ID.
  {0x3CC+4j} TARG_PID_LO[{j}] (j=0..3)
    [31:0] PID_LO_0 — Low part of Provisioned ID.
  {0x3DC+4j} TARG_CAPS[{j}] (j=0..3)
    [12:11] VTCAP2_BUS_CTX_0 — Bus Context and Conditions.
    [10] VTCAP2_ADDR_REMAP_0 — Address Remapping.
    [9:8] VTCAP2_IRQ_0 — Interrupt Requests.
    [5] VTCAP1_SHARED_DET_0 — Shared Peripheral Detect.
    [4] VTCAP1_SIDE_FX_0 — Side Effects.
    [2:0] VTCAP1_TYPE_0 — Virtual Target Type.
  {0x3EC+4j} TARG_INFO[{j}] (j=0..3) ro reset 0x2020
    [13] ENDXFER_CAND_CRC_EARLY_0 — Candidate setting for 'CRC Word Indicator.'
    [12] ENDXFER_CAND_WR_EARLY_TERM_0 — Candidate setting for 'Enable WRITE Early Termination Request.'
    [11] ENDXFER_CAND_WR_NACK_0 — Candidate setting for 'Enable ACK/NACK Capability for WRITE Command.'
    [5] ENDXFER_CRC_EARLY_0 — CRC Word Indicator.
    [4] ENDXFER_WR_EARLY_TERM_0 — Enable WRITE Early Termination Request.
    [3] ENDXFER_WR_NACK_0 — Enable ACK/NACK Capability for WRITE Command.
    [1:0] AS_0 — Activity State (ENTASn).
  {0x3FC+4j} TARG_MAX_RDWR[{j}] (j=0..3) reset 0x10000
    [31:28] RDTURN_SCALE_0 — Maximum Read Turnaround Time Scale. This value scales the Turnaround Time Value, giving the Maximum Read Turnaround Time in microseconds. max time = RDTURN_VAL << (RDTURN_SCALE + 1)
    [27:16] RDTURN_VAL_0 — Maximum Read Turnaround Time Value.
    [15:8] MAXWR_0 — Maximum Write Settings.
    [6:0] MAXRD_0 — Maximum Read Settings
  0x474 TARGEXT_EXTCAP_HEADER ro reset 0x1C0
    fields as i3c_csr[0].ID_EXTCAP_HEADER
  0x478 TERM_EXTCAP_HEADER ro reset 0x100
    fields as i3c_csr[0].ID_EXTCAP_HEADER

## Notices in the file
SPDX-License-Identifier: Apache-2.0
SPDX-FileCopyrightText: 2026 Tenstorrent USA, Inc.
